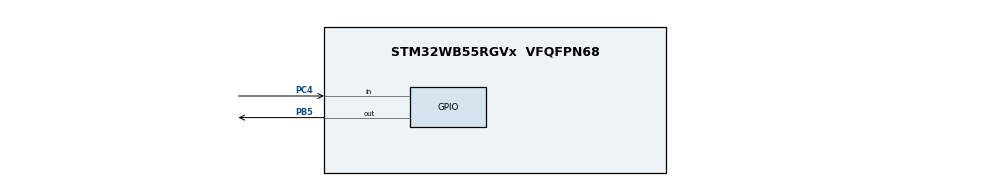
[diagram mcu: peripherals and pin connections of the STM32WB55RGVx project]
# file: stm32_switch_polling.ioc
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Mcu.Family=STM32WB
Mcu.Name=STM32WB55RGVx
Mcu.Package=VFQFPN68
NVIC.PriorityGroup=NVIC_PRIORITYGROUP_4
PB5.Signal=GPIO_Output
PC4.GPIO_PuPd=GPIO_PULLUP
PC4.Signal=GPIO_Input
ProjectManager.HeapSize=0x200
ProjectManager.StackSize=0x400
ProjectManager.TargetToolchain=STM32CubeIDE
RCC.ADCFreq_Value=48000000
RCC.AHB2CLKDivider=RCC_SYSCLK_DIV2
RCC.AHBFreq_Value=48000000
RCC.APB1Freq_Value=48000000
RCC.APB1TimFreq_Value=48000000
RCC.APB2Freq_Value=48000000
RCC.APB2TimFreq_Value=48000000
RCC.APB3Freq_Value=16000000
RCC.CortexFreq_Value=48000000
RCC.HCLKFreq_Value=48000000
RCC.HSE_VALUE=32000000
RCC.HSI48_VALUE=48000000
RCC.HSI_VALUE=16000000
RCC.PLLN=24
RCC.PLLSAI1N=24
RCC.SMPSCLockSelectionVirtual=RCC_SMPSCLKSOURCE_HSI
RCC.SMPSCLockSelectionVirtualVirtual=RCC_SMPSCLKSOURCE_HSI
RCC.SMPSDivider=1
RCC.SYSCLKFreq_VALUE=48000000
RCC.SYSCLKSource=RCC_SYSCLKSOURCE_PLLCLK
RCC.USBFreq_Value=48000000
RCC.VCOOutputFreq_Value=96000000
board=P-NUCLEO-WB55-NUCLEO

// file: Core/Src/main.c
/* USER CODE BEGIN Header */
/**
  ******************************************************************************
  * @file           : main.c
  * @brief          : Main program body
  ******************************************************************************
  * @attention
  *
  * Copyright (c) 2022 STMicroelectronics.
  * All rights reserved.
  *
  * This software is licensed under terms that can be found in the LICENSE file
  * in the root directory of this software component.
  * If no LICENSE file comes with this software, it is provided AS-IS.
  *
  ******************************************************************************
  */
/* USER CODE END Header */
#include "main.h"

void SystemClock_Config(void);
void PeriphCommonClock_Config(void);
static void MX_GPIO_Init(void);

int main(void)
{

  /* MCU Configuration--------------------------------------------------------*/

  /* Reset of all peripherals, Initializes the Flash interface and the Systick. */
  HAL_Init();

  /* Configure the system clock */
  SystemClock_Config();

/* Configure the peripherals common clocks */
  PeriphCommonClock_Config();

  /* Initialize all configured peripherals */
  MX_GPIO_Init();

  /* Infinite loop */
  while (1)
  {
    /* USER CODE BEGIN 3 */
	  if(HAL_GPIO_ReadPin(GPIOC, GPIO_PIN_4) == 0 ){
		  HAL_GPIO_WritePin(GPIOB, GPIO_PIN_5, 1);
		  HAL_Delay(500);
	  }
	  else {
		  HAL_GPIO_WritePin(GPIOB, GPIO_PIN_5, 0);
	  }
  }
  /* USER CODE END 3 */
}

void SystemClock_Config(void)
{
  RCC_OscInitTypeDef RCC_OscInitStruct = {0};
  RCC_ClkInitTypeDef RCC_ClkInitStruct = {0};

  /** Configure the main internal regulator output voltage
  */
  __HAL_PWR_VOLTAGESCALING_CONFIG(PWR_REGULATOR_VOLTAGE_SCALE1);

  /** Initializes the RCC Oscillators according to the specified parameters
  * in the RCC_OscInitTypeDef structure.
  */
  RCC_OscInitStruct.OscillatorType = RCC_OSCILLATORTYPE_HSI|RCC_OSCILLATORTYPE_MSI;
  RCC_OscInitStruct.HSIState = RCC_HSI_ON;
  RCC_OscInitStruct.MSIState = RCC_MSI_ON;
  RCC_OscInitStruct.HSICalibrationValue = RCC_HSICALIBRATION_DEFAULT;
  RCC_OscInitStruct.MSICalibrationValue = RCC_MSICALIBRATION_DEFAULT;
  RCC_OscInitStruct.MSIClockRange = RCC_MSIRANGE_6;
  RCC_OscInitStruct.PLL.PLLState = RCC_PLL_ON;
  RCC_OscInitStruct.PLL.PLLSource = RCC_PLLSOURCE_MSI;
  RCC_OscInitStruct.PLL.PLLM = RCC_PLLM_DIV1;
  RCC_OscInitStruct.PLL.PLLN = 24;
  RCC_OscInitStruct.PLL.PLLP = RCC_PLLP_DIV2;
  RCC_OscInitStruct.PLL.PLLR = RCC_PLLR_DIV2;
  RCC_OscInitStruct.PLL.PLLQ = RCC_PLLQ_DIV2;
  if (HAL_RCC_OscConfig(&RCC_OscInitStruct) != HAL_OK)
  {
    Error_Handler();
  }

  /** Configure the SYSCLKSource, HCLK, PCLK1 and PCLK2 clocks dividers
  */
  RCC_ClkInitStruct.ClockType = RCC_CLOCKTYPE_HCLK4|RCC_CLOCKTYPE_HCLK2
                              |RCC_CLOCKTYPE_HCLK|RCC_CLOCKTYPE_SYSCLK
                              |RCC_CLOCKTYPE_PCLK1|RCC_CLOCKTYPE_PCLK2;
  RCC_ClkInitStruct.SYSCLKSource = RCC_SYSCLKSOURCE_PLLCLK;
  RCC_ClkInitStruct.AHBCLKDivider = RCC_SYSCLK_DIV1;
  RCC_ClkInitStruct.APB1CLKDivider = RCC_HCLK_DIV1;
  RCC_ClkInitStruct.APB2CLKDivider = RCC_HCLK_DIV1;
  RCC_ClkInitStruct.AHBCLK2Divider = RCC_SYSCLK_DIV2;
  RCC_ClkInitStruct.AHBCLK4Divider = RCC_SYSCLK_DIV1;

  if (HAL_RCC_ClockConfig(&RCC_ClkInitStruct, FLASH_LATENCY_2) != HAL_OK)
  {
    Error_Handler();
  }
}

void PeriphCommonClock_Config(void)
{
  RCC_PeriphCLKInitTypeDef PeriphClkInitStruct = {0};

  /** Initializes the peripherals clock
  */
  PeriphClkInitStruct.PeriphClockSelection = RCC_PERIPHCLK_SMPS;
  PeriphClkInitStruct.SmpsClockSelection = RCC_SMPSCLKSOURCE_HSI;
  PeriphClkInitStruct.SmpsDivSelection = RCC_SMPSCLKDIV_RANGE0;

  if (HAL_RCCEx_PeriphCLKConfig(&PeriphClkInitStruct) != HAL_OK)
  {
    Error_Handler();
  }
}

static void MX_GPIO_Init(void)
{
  GPIO_InitTypeDef GPIO_InitStruct = {0};

  /* GPIO Ports Clock Enable */
  __HAL_RCC_GPIOC_CLK_ENABLE();
  __HAL_RCC_GPIOB_CLK_ENABLE();

  /*Configure GPIO pin Output Level */
  HAL_GPIO_WritePin(GPIOB, GPIO_PIN_5, GPIO_PIN_RESET);

  /*Configure GPIO pin : PC4 */
  GPIO_InitStruct.Pin = GPIO_PIN_4;
  GPIO_InitStruct.Mode = GPIO_MODE_INPUT;
  GPIO_InitStruct.Pull = GPIO_PULLUP;
  HAL_GPIO_Init(GPIOC, &GPIO_InitStruct);

  /*Configure GPIO pin : PB5 */
  GPIO_InitStruct.Pin = GPIO_PIN_5;
  GPIO_InitStruct.Mode = GPIO_MODE_OUTPUT_PP;
  GPIO_InitStruct.Pull = GPIO_NOPULL;
  GPIO_InitStruct.Speed = GPIO_SPEED_FREQ_LOW;
  HAL_GPIO_Init(GPIOB, &GPIO_InitStruct);

}

void Error_Handler(void)
{
  __disable_irq();
  while (1)
  {
  }
}
